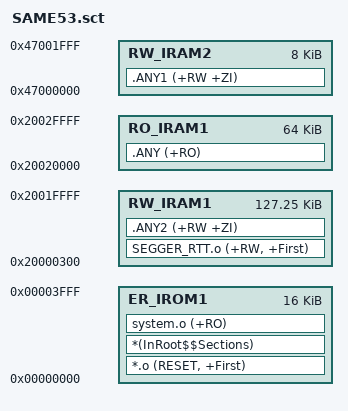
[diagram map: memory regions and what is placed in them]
; *************************************************************
; *** Scatter-Loading Description File generated by uVision ***
; *************************************************************

LR_IROM1 0x00000000 0x00004000  {    ; load region size_region
  ER_IROM1 0x00000000 0x00004000  {  ; load address = execution address
   *.o (RESET, +First)
   *(InRoot$$Sections)
    system.o (+RO)
  ;.ANY (+RO)
  }

  RO_IRAM1 0x20020000 0x000010000 {  ; RW data
   .ANY (+RO)
  }

  RW_IRAM1 0x20000300 0x00001FD00 {  ; RW data
   SEGGER_RTT.o (+RW, +First)
   .ANY2 (+RW +ZI)
  }

  RW_IRAM2 0x47000000 0x00002000 {  ; RW data
   .ANY1 (+RW +ZI)
  }
}

